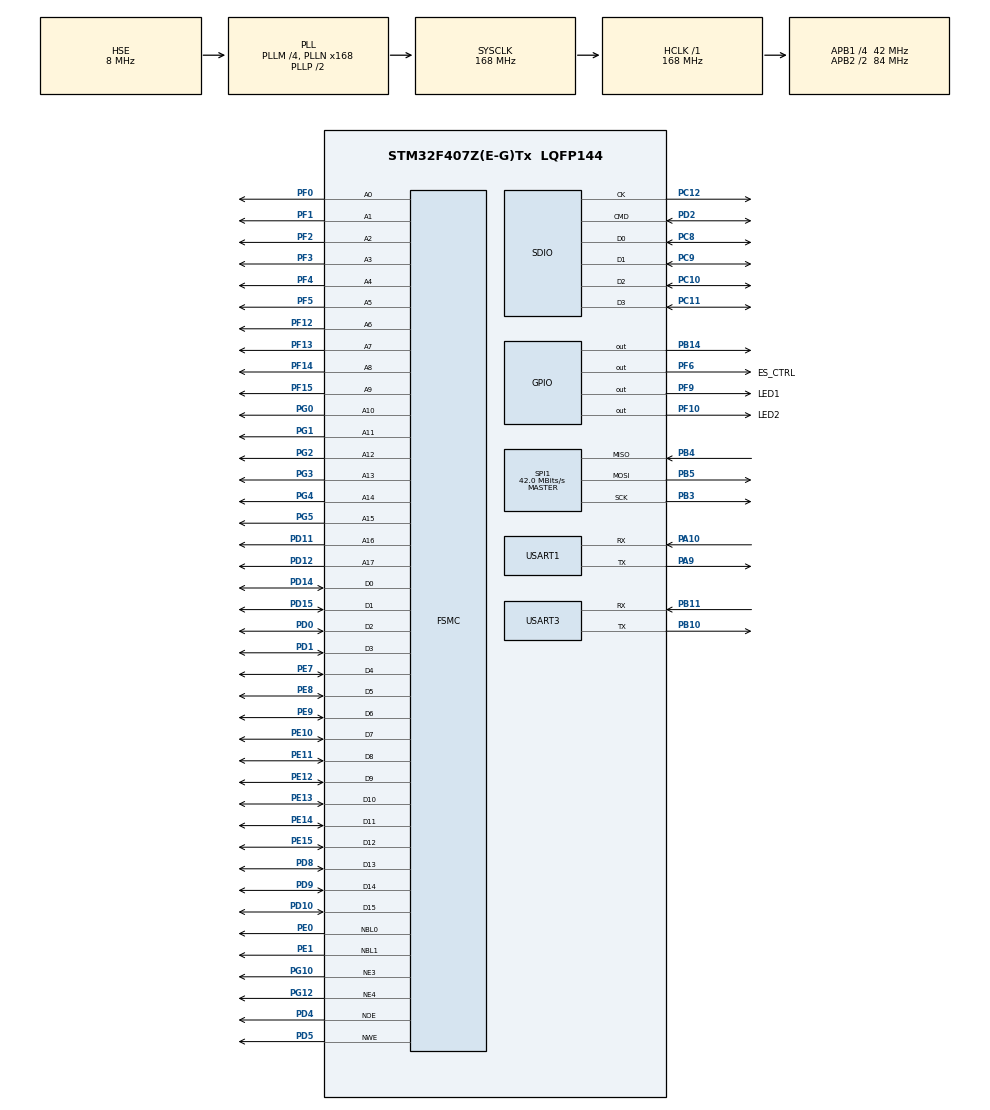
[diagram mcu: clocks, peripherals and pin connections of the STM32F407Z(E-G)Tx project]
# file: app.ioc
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Dma.Request0=SDIO_RX
Dma.Request1=SDIO_TX
Dma.SDIO_RX.0.Direction=DMA_PERIPH_TO_MEMORY
Dma.SDIO_RX.0.FIFOMode=DMA_FIFOMODE_ENABLE
Dma.SDIO_RX.0.FIFOThreshold=DMA_FIFO_THRESHOLD_FULL
Dma.SDIO_RX.0.Instance=DMA2_Stream3
Dma.SDIO_RX.0.MemBurst=DMA_MBURST_INC4
Dma.SDIO_RX.0.MemDataAlignment=DMA_MDATAALIGN_WORD
Dma.SDIO_RX.0.MemInc=DMA_MINC_ENABLE
Dma.SDIO_RX.0.Mode=DMA_PFCTRL
Dma.SDIO_RX.0.PeriphBurst=DMA_PBURST_INC4
Dma.SDIO_RX.0.PeriphDataAlignment=DMA_PDATAALIGN_WORD
Dma.SDIO_RX.0.PeriphInc=DMA_PINC_DISABLE
Dma.SDIO_RX.0.Priority=DMA_PRIORITY_MEDIUM
Dma.SDIO_TX.1.Direction=DMA_MEMORY_TO_PERIPH
Dma.SDIO_TX.1.FIFOMode=DMA_FIFOMODE_ENABLE
Dma.SDIO_TX.1.FIFOThreshold=DMA_FIFO_THRESHOLD_FULL
Dma.SDIO_TX.1.Instance=DMA2_Stream6
Dma.SDIO_TX.1.MemBurst=DMA_MBURST_INC4
Dma.SDIO_TX.1.MemDataAlignment=DMA_MDATAALIGN_WORD
Dma.SDIO_TX.1.MemInc=DMA_MINC_ENABLE
Dma.SDIO_TX.1.Mode=DMA_PFCTRL
Dma.SDIO_TX.1.PeriphBurst=DMA_PBURST_INC4
Dma.SDIO_TX.1.PeriphDataAlignment=DMA_PDATAALIGN_WORD
Dma.SDIO_TX.1.PeriphInc=DMA_PINC_DISABLE
Dma.SDIO_TX.1.Priority=DMA_PRIORITY_MEDIUM
FATFS._MAX_SS=4096
FATFS._USE_LFN=3
FREERTOS.HEAP_NUMBER=4
FREERTOS.Tasks01=defaultTask,0,1024,StartDefaultTask,Default,NULL,Dynamic,NULL,NULL;myTask02,-3,128,StartTask02,Default,NULL,Dynamic,NULL,NULL;myTask03,-3,128,StartTask03,Default,NULL,Dynamic,NULL,NULL
FSMC.AddressSetupTime1=0
FSMC.BusTurnAroundDuration1=0
FSMC.BusTurnAroundDuration2=0
FSMC.DataSetupTime1=9
FSMC.DataSetupTime2=25
FSMC.ExtendedAddressSetupTime2=8
FSMC.ExtendedBusTurnAroundDuration2=0
FSMC.ExtendedDataSetupTime2=9
FSMC.ExtendedMode2=FSMC_EXTENDED_MODE_ENABLE
FSMC.WriteOperation1=FSMC_WRITE_OPERATION_ENABLE
Mcu.Family=STM32F4
Mcu.Name=STM32F407Z(E-G)Tx
Mcu.Package=LQFP144
NVIC.DMA2_Stream3_IRQn=true\:5\:0\:false\:false\:true\:true\:false
NVIC.DMA2_Stream6_IRQn=true\:5\:0\:false\:false\:true\:true\:false
NVIC.PriorityGroup=NVIC_PRIORITYGROUP_4
NVIC.SDIO_IRQn=true\:5\:0\:false\:false\:true\:true\:true
NVIC.USART1_IRQn=true\:5\:0\:false\:false\:true\:true\:true
NVIC.USART3_IRQn=true\:5\:0\:false\:false\:true\:true\:true
PA10.Mode=Asynchronous
PA10.Signal=USART1_RX
PA13.Mode=Serial_Wire
PA13.Signal=SYS_JTMS-SWDIO
PA14.Mode=Serial_Wire
PA14.Signal=SYS_JTCK-SWCLK
PA9.Mode=Asynchronous
PA9.Signal=USART1_TX
PB10.Mode=Asynchronous
PB10.Signal=USART3_TX
PB11.Mode=Asynchronous
PB11.Signal=USART3_RX
PB14.Signal=GPIO_Output
PB3.Mode=Full_Duplex_Master
PB3.Signal=SPI1_SCK
PB4.Mode=Full_Duplex_Master
PB4.Signal=SPI1_MISO
PB5.Mode=Full_Duplex_Master
PB5.Signal=SPI1_MOSI
PC10.Mode=SD_4_bits_Wide_bus
PC10.Signal=SDIO_D2
PC11.Mode=SD_4_bits_Wide_bus
PC11.Signal=SDIO_D3
PC12.Mode=SD_4_bits_Wide_bus
PC12.Signal=SDIO_CK
PC8.Mode=SD_4_bits_Wide_bus
PC8.Signal=SDIO_D0
PC9.Mode=SD_4_bits_Wide_bus
PC9.Signal=SDIO_D1
PD0.Signal=FSMC_D2_DA2
PD1.Signal=FSMC_D3_DA3
PD10.Signal=FSMC_D15_DA15
PD11.Signal=FSMC_A16_CLE
PD12.Signal=FSMC_A17_ALE
PD14.Signal=FSMC_D0_DA0
PD15.Signal=FSMC_D1_DA1
PD2.Mode=SD_4_bits_Wide_bus
PD2.Signal=SDIO_CMD
PD4.Signal=FSMC_NOE
PD5.Signal=FSMC_NWE
PD8.Signal=FSMC_D13_DA13
PD9.Signal=FSMC_D14_DA14
PE0.Signal=FSMC_NBL0
PE1.Signal=FSMC_NBL1
PE10.Signal=FSMC_D7_DA7
PE11.Signal=FSMC_D8_DA8
PE12.Signal=FSMC_D9_DA9
PE13.Signal=FSMC_D10_DA10
PE14.Signal=FSMC_D11_DA11
PE15.Signal=FSMC_D12_DA12
PE7.Signal=FSMC_D4_DA4
PE8.Signal=FSMC_D5_DA5
PE9.Signal=FSMC_D6_DA6
PF0.Signal=FSMC_A0
PF1.Signal=FSMC_A1
PF10.GPIO_Label=LED2
PF10.GPIO_PuPd=GPIO_PULLUP
PF10.PinState=GPIO_PIN_SET
PF10.Signal=GPIO_Output
PF12.Signal=FSMC_A6
PF13.Signal=FSMC_A7
PF14.Signal=FSMC_A8
PF15.Signal=FSMC_A9
PF2.Signal=FSMC_A2
PF3.Signal=FSMC_A3
PF4.Signal=FSMC_A4
PF5.Signal=FSMC_A5
PF6.GPIO_Label=ES_CTRL
PF6.GPIO_ModeDefaultOutputPP=GPIO_MODE_OUTPUT_PP
PF6.GPIO_PuPd=GPIO_PULLUP
PF6.GPIO_Speed=GPIO_SPEED_FREQ_LOW
PF6.PinState=GPIO_PIN_SET
PF6.Signal=GPIO_Output
PF9.GPIO_Label=LED1
PF9.GPIO_PuPd=GPIO_PULLUP
PF9.PinState=GPIO_PIN_SET
PF9.Signal=GPIO_Output
PG0.Signal=FSMC_A10
PG1.Signal=FSMC_A11
PG10.Mode=NorPsramChipSelect3_1
PG10.Signal=FSMC_NE3
PG12.Mode=NorPsramChipSelect4_2
PG12.Signal=FSMC_NE4
PG2.Signal=FSMC_A12
PG3.Signal=FSMC_A13
PG4.Signal=FSMC_A14
PG5.Signal=FSMC_A15
PH0-OSC_IN.Mode=HSE-External-Oscillator
PH0-OSC_IN.Signal=RCC_OSC_IN
PH1-OSC_OUT.Mode=HSE-External-Oscillator
PH1-OSC_OUT.Signal=RCC_OSC_OUT
ProjectManager.HeapSize=0x800
ProjectManager.StackSize=0x800
ProjectManager.TargetToolchain=MDK-ARM V5
RCC.48MHZClocksFreq_Value=48000000
RCC.AHBFreq_Value=168000000
RCC.APB1CLKDivider=RCC_HCLK_DIV4
RCC.APB1Freq_Value=42000000
RCC.APB1TimFreq_Value=84000000
RCC.APB2CLKDivider=RCC_HCLK_DIV2
RCC.APB2Freq_Value=84000000
RCC.APB2TimFreq_Value=168000000
RCC.CortexFreq_Value=168000000
RCC.HCLKFreq_Value=168000000
RCC.HSE_VALUE=8000000
RCC.HSI_VALUE=16000000
RCC.LSE_VALUE=32768
RCC.PLLM=4
RCC.PLLN=168
RCC.PLLQ=7
RCC.PLLSourceVirtual=RCC_PLLSOURCE_HSE
RCC.SYSCLKFreq_VALUE=168000000
RCC.SYSCLKSource=RCC_SYSCLKSOURCE_PLLCLK
RCC.VCOOutputFreq_Value=336000000
SH.FSMC_A0.0=FSMC_A0,18b-a1
SH.FSMC_A1.0=FSMC_A1,18b-a1
SH.FSMC_A10.0=FSMC_A10,18b-a1
SH.FSMC_A11.0=FSMC_A11,18b-a1
SH.FSMC_A12.0=FSMC_A12,18b-a1
SH.FSMC_A13.0=FSMC_A13,18b-a1
SH.FSMC_A14.0=FSMC_A14,18b-a1
SH.FSMC_A15.0=FSMC_A15,18b-a1
SH.FSMC_A16_CLE.0=FSMC_A16,18b-a1
SH.FSMC_A17_ALE.0=FSMC_A17,18b-a1
SH.FSMC_A2.0=FSMC_A2,18b-a1
SH.FSMC_A3.0=FSMC_A3,18b-a1
SH.FSMC_A4.0=FSMC_A4,18b-a1
SH.FSMC_A5.0=FSMC_A5,18b-a1
SH.FSMC_A6.0=FSMC_A6,18b-a1
SH.FSMC_A6.1=FSMC_A6,A6_2
SH.FSMC_A7.0=FSMC_A7,18b-a1
SH.FSMC_A8.0=FSMC_A8,18b-a1
SH.FSMC_A9.0=FSMC_A9,18b-a1
SH.FSMC_D0_DA0.0=FSMC_D0,16b-d1
SH.FSMC_D0_DA0.1=FSMC_D0,16b-d2
SH.FSMC_D10_DA10.0=FSMC_D10,16b-d1
SH.FSMC_D10_DA10.1=FSMC_D10,16b-d2
SH.FSMC_D11_DA11.0=FSMC_D11,16b-d1
SH.FSMC_D11_DA11.1=FSMC_D11,16b-d2
SH.FSMC_D12_DA12.0=FSMC_D12,16b-d1
SH.FSMC_D12_DA12.1=FSMC_D12,16b-d2
SH.FSMC_D13_DA13.0=FSMC_D13,16b-d1
SH.FSMC_D13_DA13.1=FSMC_D13,16b-d2
SH.FSMC_D14_DA14.0=FSMC_D14,16b-d1
SH.FSMC_D14_DA14.1=FSMC_D14,16b-d2
SH.FSMC_D15_DA15.0=FSMC_D15,16b-d1
SH.FSMC_D15_DA15.1=FSMC_D15,16b-d2
SH.FSMC_D1_DA1.0=FSMC_D1,16b-d1
SH.FSMC_D1_DA1.1=FSMC_D1,16b-d2
SH.FSMC_D2_DA2.0=FSMC_D2,16b-d1
SH.FSMC_D2_DA2.1=FSMC_D2,16b-d2
SH.FSMC_D3_DA3.0=FSMC_D3,16b-d1
SH.FSMC_D3_DA3.1=FSMC_D3,16b-d2
SH.FSMC_D4_DA4.0=FSMC_D4,16b-d1
SH.FSMC_D4_DA4.1=FSMC_D4,16b-d2
SH.FSMC_D5_DA5.0=FSMC_D5,16b-d1
SH.FSMC_D5_DA5.1=FSMC_D5,16b-d2
SH.FSMC_D6_DA6.0=FSMC_D6,16b-d1
SH.FSMC_D6_DA6.1=FSMC_D6,16b-d2
SH.FSMC_D7_DA7.0=FSMC_D7,16b-d1
SH.FSMC_D7_DA7.1=FSMC_D7,16b-d2
SH.FSMC_D8_DA8.0=FSMC_D8,16b-d1
SH.FSMC_D8_DA8.1=FSMC_D8,16b-d2
SH.FSMC_D9_DA9.0=FSMC_D9,16b-d1
SH.FSMC_D9_DA9.1=FSMC_D9,16b-d2
SH.FSMC_NBL0.0=FSMC_NBL0,2ByteEnable1
SH.FSMC_NBL1.0=FSMC_NBL1,2ByteEnable1
SH.FSMC_NOE.0=FSMC_NOE,Sram1
SH.FSMC_NOE.1=FSMC_NOE,Lcd2
SH.FSMC_NWE.0=FSMC_NWE,Sram1
SH.FSMC_NWE.1=FSMC_NWE,Lcd2
SPI1.CLKPhase=SPI_PHASE_2EDGE
SPI1.CLKPolarity=SPI_POLARITY_HIGH
SPI1.CRCCalculation=SPI_CRCCALCULATION_DISABLE
SPI1.CalculateBaudRate=42.0 MBits/s
SPI1.Direction=SPI_DIRECTION_2LINES
SPI1.Mode=SPI_MODE_MASTER
SPI1.VirtualType=VM_MASTER
USART1.VirtualMode=VM_ASYNC
USART3.VirtualMode=VM_ASYNC
VP_CRC_VS_CRC.Mode=CRC_Activate
VP_FATFS_VS_SDIO.Mode=SDIO
VP_FREERTOS_VS_ENABLE.Mode=Enabled
board=custom

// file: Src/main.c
/**
  ******************************************************************************
  * @file           : main.c
  * @brief          : Main program body
  ******************************************************************************
  * This notice applies to any and all portions of this file
  * that are not between comment pairs USER CODE BEGIN and
  * USER CODE END. Other portions of this file, whether
  * inserted by the user or by software development tools
  * are owned by their respective copyright owners.
  *
  * Copyright (c) 2018 STMicroelectronics International N.V.
  * All rights reserved.
  *
  * Redistribution and use in source and binary forms, with or without
  * modification, are permitted, provided that the following conditions are met:
  *
  * 1. Redistribution of source code must retain the above copyright notice,
  *    this list of conditions and the following disclaimer.
  * 2. Redistributions in binary form must reproduce the above copyright notice,
  *    this list of conditions and the following disclaimer in the documentation
  *    and/or other materials provided with the distribution.
  * 3. Neither the name of STMicroelectronics nor the names of other
  *    contributors to this software may be used to endorse or promote products
  *    derived from this software without specific written permission.
  * 4. This software, including modifications and/or derivative works of this
  *    software, must execute solely and exclusively on microcontroller or
  *    microprocessor devices manufactured by or for STMicroelectronics.
  * 5. Redistribution and use of this software other than as permitted under
  *    this license is void and will automatically terminate your rights under
  *    this license.
  *
  * THIS SOFTWARE IS PROVIDED BY STMICROELECTRONICS AND CONTRIBUTORS "AS IS"
  * AND ANY EXPRESS, IMPLIED OR STATUTORY WARRANTIES, INCLUDING, BUT NOT
  * LIMITED TO, THE IMPLIED WARRANTIES OF MERCHANTABILITY, FITNESS FOR A
  * PARTICULAR PURPOSE AND NON-INFRINGEMENT OF THIRD PARTY INTELLECTUAL PROPERTY
  * RIGHTS ARE DISCLAIMED TO THE FULLEST EXTENT PERMITTED BY LAW. IN NO EVENT
  * SHALL STMICROELECTRONICS OR CONTRIBUTORS BE LIABLE FOR ANY DIRECT, INDIRECT,
  * INCIDENTAL, SPECIAL, EXEMPLARY, OR CONSEQUENTIAL DAMAGES (INCLUDING, BUT NOT
  * LIMITED TO, PROCUREMENT OF SUBSTITUTE GOODS OR SERVICES; LOSS OF USE, DATA,
  * OR PROFITS; OR BUSINESS INTERRUPTION) HOWEVER CAUSED AND ON ANY THEORY OF
  * LIABILITY, WHETHER IN CONTRACT, STRICT LIABILITY, OR TORT (INCLUDING
  * NEGLIGENCE OR OTHERWISE) ARISING IN ANY WAY OUT OF THE USE OF THIS SOFTWARE,
  * EVEN IF ADVISED OF THE POSSIBILITY OF SUCH DAMAGE.
  *
  ******************************************************************************
  */
#include "main.h"
#include "stm32f4xx_hal.h"
#include "cmsis_os.h"
#include "crc.h"
#include "dma.h"
#include "fatfs.h"
#include "sdio.h"
#include "spi.h"
#include "usart.h"
#include "gpio.h"
#include "fsmc.h"

/* USER CODE BEGIN PV */
/* Private variables ---------------------------------------------------------*/

/* USER CODE END PV */

void SystemClock_Config(void);
void MX_FREERTOS_Init(void);

/* USER CODE BEGIN PFP */
/* Private function prototypes -----------------------------------------------*/

/* USER CODE END PFP */

int main(void)
{

  /* MCU Configuration----------------------------------------------------------*/

  /* Reset of all peripherals, Initializes the Flash interface and the Systick. */
  HAL_Init();

  /* Configure the system clock */
  SystemClock_Config();

  /* Initialize all configured peripherals */
  MX_GPIO_Init();
  MX_DMA_Init();
  MX_CRC_Init();
  MX_FSMC_Init();
  MX_SPI1_Init();
  MX_USART1_UART_Init();
  MX_SDIO_SD_Init();
  MX_USART3_UART_Init();
  /* USER CODE BEGIN 2 */
	//vPortDefineHeapRegions(xHeapRegions);
  /* USER CODE END 2 */

  /* Call init function for freertos objects (in freertos.c) */
  MX_FREERTOS_Init();

  /* Start scheduler */
  osKernelStart();

  /* We should never get here as control is now taken by the scheduler */

  /* Infinite loop */
  while (1)
  {

  }

}

void SystemClock_Config(void)
{

  RCC_OscInitTypeDef RCC_OscInitStruct;
  RCC_ClkInitTypeDef RCC_ClkInitStruct;

    /**Configure the main internal regulator output voltage
    */
  __HAL_RCC_PWR_CLK_ENABLE();

  __HAL_PWR_VOLTAGESCALING_CONFIG(PWR_REGULATOR_VOLTAGE_SCALE1);

    /**Initializes the CPU, AHB and APB busses clocks
    */
  RCC_OscInitStruct.OscillatorType = RCC_OSCILLATORTYPE_HSE;
  RCC_OscInitStruct.HSEState = RCC_HSE_ON;
  RCC_OscInitStruct.PLL.PLLState = RCC_PLL_ON;
  RCC_OscInitStruct.PLL.PLLSource = RCC_PLLSOURCE_HSE;
  RCC_OscInitStruct.PLL.PLLM = 4;
  RCC_OscInitStruct.PLL.PLLN = 168;
  RCC_OscInitStruct.PLL.PLLP = RCC_PLLP_DIV2;
  RCC_OscInitStruct.PLL.PLLQ = 7;
  if (HAL_RCC_OscConfig(&RCC_OscInitStruct) != HAL_OK)
  {
    _Error_Handler(__FILE__, __LINE__);
  }

    /**Initializes the CPU, AHB and APB busses clocks
    */
  RCC_ClkInitStruct.ClockType = RCC_CLOCKTYPE_HCLK|RCC_CLOCKTYPE_SYSCLK
                              |RCC_CLOCKTYPE_PCLK1|RCC_CLOCKTYPE_PCLK2;
  RCC_ClkInitStruct.SYSCLKSource = RCC_SYSCLKSOURCE_PLLCLK;
  RCC_ClkInitStruct.AHBCLKDivider = RCC_SYSCLK_DIV1;
  RCC_ClkInitStruct.APB1CLKDivider = RCC_HCLK_DIV4;
  RCC_ClkInitStruct.APB2CLKDivider = RCC_HCLK_DIV2;

  if (HAL_RCC_ClockConfig(&RCC_ClkInitStruct, FLASH_LATENCY_5) != HAL_OK)
  {
    _Error_Handler(__FILE__, __LINE__);
  }

    /**Configure the Systick interrupt time
    */
  HAL_SYSTICK_Config(HAL_RCC_GetHCLKFreq()/1000);

    /**Configure the Systick
    */
  HAL_SYSTICK_CLKSourceConfig(SYSTICK_CLKSOURCE_HCLK);

  /* SysTick_IRQn interrupt configuration */
  HAL_NVIC_SetPriority(SysTick_IRQn, 15, 0);
}

void _Error_Handler(char *file, int line)
{
  /* USER CODE BEGIN Error_Handler_Debug */
  /* User can add his own implementation to report the HAL error return state */
	#include "load.h"
	savePackInfo();
	saveLoadInfo();
	_Log("file=%s line=%d",file,line);
  while(1)
  {
		osDelay(2000);
  }
  /* USER CODE END Error_Handler_Debug */
}

/************************ (C) COPYRIGHT STMicroelectronics *****END OF FILE****/

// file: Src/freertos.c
/**
  ******************************************************************************
  * File Name          : freertos.c
  * Description        : Code for freertos applications
  ******************************************************************************
  * This notice applies to any and all portions of this file
  * that are not between comment pairs USER CODE BEGIN and
  * USER CODE END. Other portions of this file, whether
  * inserted by the user or by software development tools
  * are owned by their respective copyright owners.
  *
  * Copyright (c) 2018 STMicroelectronics International N.V.
  * All rights reserved.
  *
  * Redistribution and use in source and binary forms, with or without
  * modification, are permitted, provided that the following conditions are met:
  *
  * 1. Redistribution of source code must retain the above copyright notice,
  *    this list of conditions and the following disclaimer.
  * 2. Redistributions in binary form must reproduce the above copyright notice,
  *    this list of conditions and the following disclaimer in the documentation
  *    and/or other materials provided with the distribution.
  * 3. Neither the name of STMicroelectronics nor the names of other
  *    contributors to this software may be used to endorse or promote products
  *    derived from this software without specific written permission.
  * 4. This software, including modifications and/or derivative works of this
  *    software, must execute solely and exclusively on microcontroller or
  *    microprocessor devices manufactured by or for STMicroelectronics.
  * 5. Redistribution and use of this software other than as permitted under
  *    this license is void and will automatically terminate your rights under
  *    this license.
  *
  * THIS SOFTWARE IS PROVIDED BY STMICROELECTRONICS AND CONTRIBUTORS "AS IS"
  * AND ANY EXPRESS, IMPLIED OR STATUTORY WARRANTIES, INCLUDING, BUT NOT
  * LIMITED TO, THE IMPLIED WARRANTIES OF MERCHANTABILITY, FITNESS FOR A
  * PARTICULAR PURPOSE AND NON-INFRINGEMENT OF THIRD PARTY INTELLECTUAL PROPERTY
  * RIGHTS ARE DISCLAIMED TO THE FULLEST EXTENT PERMITTED BY LAW. IN NO EVENT
  * SHALL STMICROELECTRONICS OR CONTRIBUTORS BE LIABLE FOR ANY DIRECT, INDIRECT,
  * INCIDENTAL, SPECIAL, EXEMPLARY, OR CONSEQUENTIAL DAMAGES (INCLUDING, BUT NOT
  * LIMITED TO, PROCUREMENT OF SUBSTITUTE GOODS OR SERVICES; LOSS OF USE, DATA,
  * OR PROFITS; OR BUSINESS INTERRUPTION) HOWEVER CAUSED AND ON ANY THEORY OF
  * LIABILITY, WHETHER IN CONTRACT, STRICT LIABILITY, OR TORT (INCLUDING
  * NEGLIGENCE OR OTHERWISE) ARISING IN ANY WAY OUT OF THE USE OF THIS SOFTWARE,
  * EVEN IF ADVISED OF THE POSSIBILITY OF SUCH DAMAGE.
  *
  ******************************************************************************
  */

#include "FreeRTOS.h"
#include "task.h"
#include "cmsis_os.h"

/* USER CODE BEGIN Includes */
#include "ff.h"
#include "comm.h"
/* USER CODE END Includes */

osThreadId defaultTaskHandle;
osThreadId myTask02Handle;
osThreadId myTask03Handle;

void StartDefaultTask(void const * argument);
void StartTask02(void const * argument);
void StartTask03(void const * argument);

extern void MX_FATFS_Init(void);
void MX_FREERTOS_Init(void); /* (MISRA C 2004 rule 8.1) */

/* Hook prototypes */

/* Init FreeRTOS */

void MX_FREERTOS_Init(void) {

  /* Create the thread(s) */
  /* definition and creation of defaultTask */
  osThreadDef(defaultTask, StartDefaultTask, osPriorityNormal, 0, 1024);
  defaultTaskHandle = osThreadCreate(osThread(defaultTask), NULL);

  /* definition and creation of myTask02 */
  osThreadDef(myTask02, StartTask02, osPriorityIdle, 0, 128);
  myTask02Handle = osThreadCreate(osThread(myTask02), NULL);

  /* definition and creation of myTask03 */
  osThreadDef(myTask03, StartTask03, osPriorityIdle, 0, 128);
  myTask03Handle = osThreadCreate(osThread(myTask03), NULL);

  /* USER CODE BEGIN RTOS_QUEUES */
  /* add queues, ... */
	_Log("APP:-----");
  /* USER CODE END RTOS_QUEUES */
}

/* StartDefaultTask function */
void StartDefaultTask(void const * argument)
{
  /* init code for FATFS */
  MX_FATFS_Init();

  /* USER CODE BEGIN StartDefaultTask */

  /* Infinite loop */
  for(;;)
  {
    osDelay(100);
		CommTask();
  }
  /* USER CODE END StartDefaultTask */
}

/* StartTask02 function */
void StartTask02(void const * argument)
{
  /* USER CODE BEGIN StartTask02 */
  /* Infinite loop */
  for(;;)
  {

		HAL_GPIO_TogglePin(GPIOF,LED1_Pin);
    osDelay(200);
  }
  /* USER CODE END StartTask02 */
}

/* StartTask03 function */
void StartTask03(void const * argument)
{
  /* USER CODE BEGIN StartTask03 */
  /* Infinite loop */
  for(;;)
  {
		HAL_GPIO_TogglePin(GPIOF,LED2_Pin);
    osDelay(200);
  }
  /* USER CODE END StartTask03 */
}

/************************ (C) COPYRIGHT STMicroelectronics *****END OF FILE****/
